# SN32F770 register map
Vendor: SONiX Technology Co., Ltd.; Series: SN32F770; File version: 1.4
ARM 32-bit Cortex-M0 Microcontroller based device, CPU clock up to 48MHz, etc.
CPU: CM0 r0p0, little endian, no MPU, no FPU, 2 interrupt priority bits
Registers are 32-bit, read-write, reset 0x0 unless marked. A register's access mark holds for its fields unless they carry their own. Offsets are from the block's base; lines under a group give offsets from that group; [hi:lo] are bit positions; {n}, {i} and the like mark numbered series; 'fields as' and 'values as' point back to an identical list; <NAME> marks a mode.

## Memory map
0x1FFF2224 SN_UC size 0x2000 — UC Registers
0x40000000 SN_CT16B0 size 0x2000 — 16-bit Timer 0 with Capture function
0x40002000 SN_CT16B1 size 0x2000 — 16-bit Timer 1 with Capture function
0x40010000 SN_WDT size 0x2000 — Watchdog Timer
0x40016000 SN_UART0 size 0x2000 — UART0
0x40026000 SN_ADC size 0x2000 — ADC
0x40028000 SN_CMP size 0x2000 — Comparator
0x40032000 SN_PMU size 0x2000 — Power Management Unit
0x40044000 SN_GPIO0 size 0x2000 — General Purpose I/O
0x40046000 SN_GPIO1 size 0x2000 — General Purpose I/O
0x40048000 SN_GPIO2 size 0x2000 — General Purpose I/O
0x4005E000 SN_SYS1 size 0x2000 — System Control Registers
0x40060000 SN_SYS0 size 0x2000 — System Control Registers 0
0x40062000 SN_FLASH size 0x2000 — FLASH Memory Control Registers

## Interrupts
0 NDT (SN_SYS0)
1 CT16B0 (SN_CT16B0)
2 CT16B1 (SN_CT16B1)
3 ADC (SN_ADC)
8 CMP0 (SN_CMP)
9 UART0 (SN_UART0)
11 WDT (SN_WDT)
12 LVD (SN_SYS0)
13 P2 (SN_GPIO2)
14 P1 (SN_GPIO1)
15 P0 (SN_GPIO0)

## SN_SYS0 — System Control Registers 0
Base 0x40060000
0x00 ANBCTRL reset 0x1 — Offset:0x00 Analog Block Control Register
  [2:0] IHRCEN — IHRC enable
    0=Disable IHRC; 1=IHRC 12MHz (Enable IHRC 12MHz for HCLK); 2=IHRC 24MHz (Enable IHRC 24MHz for HCLK); 4=IHRC 48MHz (Enable IHRC 48MHz for HCLK)
0x08 CSST ro reset 0x1 — Offset:0x08 Clock Source Status Register
  [0] IHRCRDY — IHRC ready flag
    0=IHRC is Not Ready; 1=IHRC is Ready
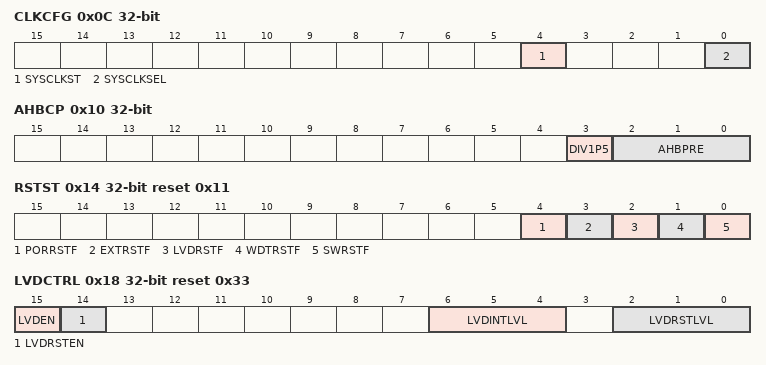
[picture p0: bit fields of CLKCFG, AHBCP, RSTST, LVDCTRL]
0x0C CLKCFG — Offset:0x0C System Clock Configuration Register
  [4] SYSCLKST ro — System clock switch status
    0=IHRC (IHRC is used as system clock); 1=ILRC (ILRC is used as system clock)
  [0] SYSCLKSEL — System clock source selection
    0=IHRC (HCLK=IHRC); 1=ILRC (HCLK=ILRC)
0x10 AHBCP — Offset:0x10 AHB Clock Prescale Register
  [3] DIV1P5 — SYSCLK prescaler
    0=DIV1 (SYSCLK = SYSCLK/1); 1=DIV1P5 (SYSCLK = SYSCLK/1.5)
  [2:0] AHBPRE — AHB clock source prescaler
    0=000b (FAHB=FSYSCLK/1); 1=001b (FAHB=FSYSCLK/2); 2=010b (FAHB=FSYSCLK/4); 3=011b (FAHB=FSYSCLK/8); 4=100b (FAHB=FSYSCLK/16); 5=101b (FAHB=FSYSCLK/32); 6=110b (FAHB=FSYSCLK/64); 7=111b (FAHB=FSYSCLK/128)
0x14 RSTST reset 0x11 — Offset:0x14 System Reset Status Register
  [4] PORRSTF — POR reset flag
    0=No POR occurred; 1=POR occurred
  [3] EXTRSTF — External reset flag
    0=No Extenral reset occurred; 1=External reset occurred
  [2] LVDRSTF — LVD reset flag
    0=No LVD reset occurred; 1=LVD reset occurred
  [1] WDTRSTF — WDT reset flag
    0=No WDT reset occurred; 1=WDT reset occurred
  [0] SWRSTF — Software reset flag
    0=No SW reset occurred; 1=SW reset occurred
0x18 LVDCTRL reset 0x33 — Offset:0x18 LVD Control Register
  [15] LVDEN — LVD enable
    0=Diable (Disable LVD); 1=Enable LVD
  [14] LVDRSTEN — LVD Reset enable
    0=Diable (Disable LVD reset); 1=Enable LVD reset
  [6:4] LVDINTLVL — LVD interrupt level
    3=2.70V (LVD interrupt threshold is 2.70V); 4=3.00V (LVD interrupt threshold is 3.00V); 5=3.60V (LVD interrupt threshold is 3.60V)
  [2:0] LVDRSTLVL — LVD reset level
    3=2.70V (LVD reset threshold is 2.70V); 4=3.00V (LVD reset threshold is 3.00V); 5=3.60V (LVD reset threshold is 3.60V)
0x1C EXRSTCTRL reset 0x1 — Offset:0x1C External Reset Pin Control Register
  [0] RESETDIS — External reset pin disable
    0=Enable (P0.7 acts as nRESET pin); 1=Disable (P0.7 acts as GPIO pin)
0x20 SWDCTRL — Offset:0x20 SWD Pin Control Register
  [0] SWDDIS — SWD pin disable
    0=Enable SWD pins; 1=Disable SWD pins
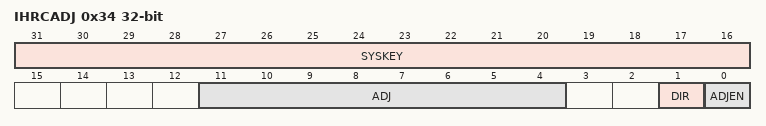
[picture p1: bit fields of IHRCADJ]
0x34 IHRCADJ — Offset:0x34 IHRC Frequency Adjustment register
  [31:16] SYSKEY wo — System register key
  [11:4] ADJ — IHRC frequency adjusting bits
  [1] DIR — IHRC frequency adjusting direction bit
    0=Positive; 1=Negative
  [0] ADJEN — IHRC frequency adjustment enable bit
    0=Disable; 1=Enable

## Licence text in the file
ARM Limited (ARM) is supplying this software for use with Cortex-M processor based microcontroller, but can be equally used for other suitable processor architectures. This file can be freely distributed. Modifications to this file shall be clearly marked. . THIS SOFTWARE IS PROVIDED "AS IS". NO WARRANTIES, WHETHER EXPRESS, IMPLIED. OR STATUTORY, INCLUDING, BUT NOT LIMITED TO, IMPLIED WARRANTIES OF. MERCHANTABILITY AND FITNESS FOR A PARTICULAR PURPOSE APPLY TO THIS SOFTWARE. ARM SHALL NOT, IN ANY CIRCUMSTANCES, BE LIABLE FOR SPECIAL, INCIDENTAL, OR. CONSEQUENTIAL DAMAGES, FOR ANY REASON WHATSOEVER.

## Notices in the file
Copyright (C) 2019 ARM Limited. All rights reserved.
